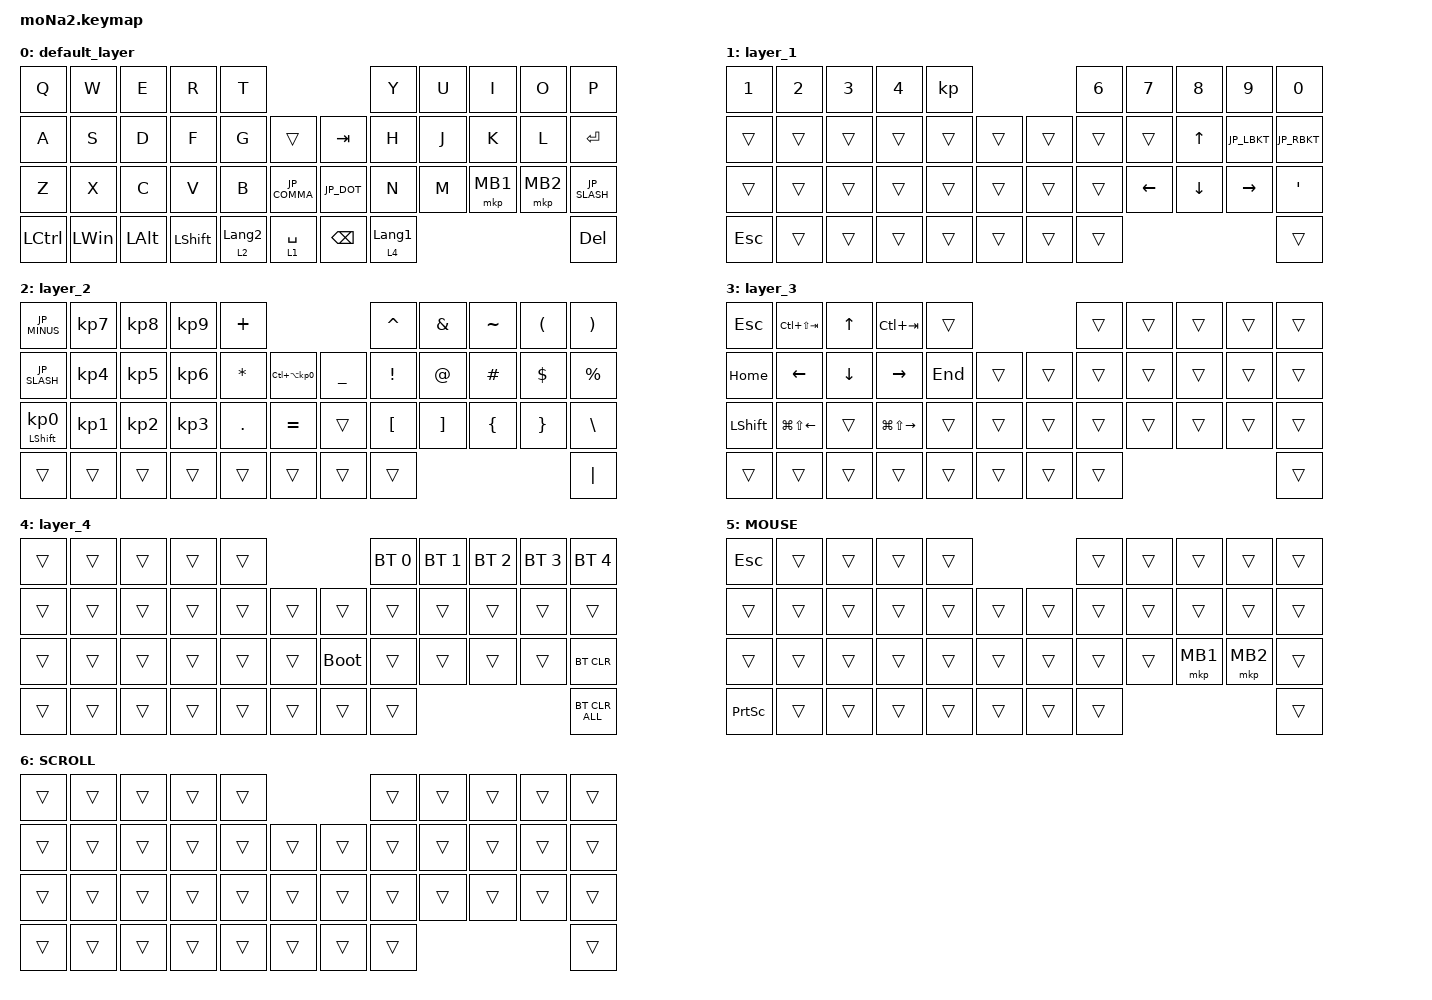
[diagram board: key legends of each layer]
#include <behaviors.dtsi>
#include <dt-bindings/zmk/bt.h>
#include <dt-bindings/zmk/keys.h>
#include <dt-bindings/zmk/pointing.h>

#define ZMK_POINTING_DEFAULT_SCRL_VAL 100
#define MOUSE 5
#define SCROLL 6

#define JP_ZKHK  GRAVE        // Zenkaku ↔ Hankaku ↔ Kanji (半角 ↔ 全角 ↔ 漢字)
#define JP_MINUS MINUS        // -
#define JP_CARET EQUAL        // ^
#define JP_YEN   INT3         // ¥
#define JP_AT    LBKT         // @
#define JP_LBKT  RBKT         // [
#define JP_EISU  CAPS         // Eisū (英数)
#define JP_SEMI  SEMI         // ;
#define JP_COLON SQT          // :
#define JP_RBKT  NUHS         // ]
#define JP_COMMA COMMA        // ,
#define JP_DOT   DOT          // .
#define JP_SLASH SLASH        // /
#define JP_BSLH  INT1         // (backslash)
#define JP_MHEN  INT5         // Muhenkan (無変換)
#define JP_HENK  INT4         // Henkan (変換)
#define JP_KANA  INT2         // Katakana ↔ Hiragana ↔ Rōmaji (カタカナ ↔ ひらがな ↔ ローマ字)
#define JP_EXCL  LS(N1)       // !
#define JP_DQT   LS(N2)       // "
#define JP_HASH  LS(N3)       // #
#define JP_DLLR  LS(N4)       // $
#define JP_PRCNT LS(N5)       // %
#define JP_AMPS  LS(N6)       // &
#define JP_SQT   LS(N7)       // '
#define JP_LPAR  LS(N8)       // (
#define JP_RPAR  LS(N9)       // )
#define JP_EQUAL LS(JP_MINUS) // =
#define JP_TILDE LS(JP_CARET) // ~
#define JP_PIPE  LS(JP_YEN)   // |
#define JP_GRAVE LS(JP_AT)    // `
#define JP_LBRC  LS(JP_LBKT)  // {
#define JP_CAPS  LS(JP_EISU)  // Caps Lock
#define JP_PLUS  LS(JP_SEMI)  // +
#define JP_ASTRK LS(JP_COLON) // *
#define JP_RBRC  LS(JP_RBKT)  // }
#define JP_LT    LS(JP_COMMA) // <
#define JP_RT    LS(JP_DOT)   // >
#define JP_QMARK LS(JP_SLASH) // ?
#define JP_UNDER LS(JP_BSLH)  // _

&mt {
    flavor = "balanced";
    quick-tap-ms = <0>;
};

/ {
    combos {
        compatible = "zmk,combos";

        minus {
            bindings = <&kp JP_MINUS>;
            key-positions = <7 6>;
            layers = <0>;
        };

        exclamation {
            bindings = <&kp JP_EXCL>;
            key-positions = <0 1>;
            layers = <0>;
        };

        question {
            bindings = <&kp JP_QMARK>;
            key-positions = <32 33>;
        };

        tab {
            bindings = <&kp TAB>;
            key-positions = <10 11>;
        };

        period {
            bindings = <&kp JP_DOT>;
            key-positions = <32 31>;
        };

        comma {
            bindings = <&kp JP_COMMA>;
            key-positions = <31 30>;
        };

        nyoro {
            bindings = <&kp JP_TILDE>;
            key-positions = <7 8>;
        };

        atmark {
            bindings = <&kp JP_AT>;
            key-positions = <19 20>;
        };

        colon {
            bindings = <&kp JP_COLON>;
            key-positions = <20 21>;
        };
    };

    macros {
        to_layer_0: to_layer_0 {
            compatible = "zmk,behavior-macro-one-param";
            #binding-cells = <1>;
            bindings = <&to 0 &macro_param_1to1 &kp MACRO_PLACEHOLDER>;
            label = "TO_LAYER_0";
        };
    };

    behaviors {
        lt_to_layer_0: lt_to_layer_0 {
            compatible = "zmk,behavior-hold-tap";
            label = "LAYER_TAP_TO_0";
            bindings = <&mo>, <&to_layer_0>;

            #binding-cells = <2>;
            tapping-term-ms = <200>;
        };

        scroll_up_down: behavior_sensor_rotate_mouse_wheel_up_down {
            compatible = "zmk,behavior-sensor-rotate";
            #sensor-binding-cells = <0>;
            bindings = <&msc SCRL_UP>, <&msc SCRL_DOWN>;

            tap-ms = <20>;
        };
    };

    keymap {
        compatible = "zmk,keymap";

        default_layer {
            bindings = <
&kp Q      &kp W         &kp E         &kp R                      &kp T                                      &kp Y             &kp U  &kp I     &kp O     &kp P
&kp A      &kp S         &kp D         &kp F                      &kp G        &trans         &kp TAB      &kp H             &kp J  &kp K     &kp L     &kp ENTER
&kp Z      &kp X         &kp C         &kp V                      &kp B        &kp JP_COMMA    &kp JP_DOT      &kp N             &kp M  &mkp MB1  &mkp MB2  &kp JP_SLASH
&kp LCTRL  &kp LEFT_WIN  &kp LEFT_ALT  &kp LEFT_SHIFT  &lt 2 LANGUAGE_2  &lt 1 SPACE      &kp BACKSPACE  &lt 4 LANGUAGE_1                             &kp DELETE
            >;

            sensor-bindings =
                <&scroll_up_down>,
                <&inc_dec_kp C_VOL_DN C_VOL_UP>;
        };

        layer_1 {
            bindings = <
&kp NUMBER_1  &kp NUMBER_2  &kp NUMBER_3  &kp NUMBER_4  &kp                     &kp NUMBER_6  &kp N7    &kp N8          &kp N9            &kp N0
&trans        &trans        &trans        &trans        &trans  &trans    &trans  &trans        &trans    &kp UP_ARROW    &kp JP_LBKT     &kp JP_RBKT
&trans        &trans        &trans        &trans        &trans  &trans    &trans  &trans        &kp LEFT  &kp DOWN_ARROW  &kp RIGHT         &kp SQT
&kp ESCAPE    &trans        &trans        &trans        &trans  &trans    &trans  &trans                                                    &trans
            >;

            sensor-bindings = <&scroll_up_down>;
        };

        layer_2 {
            bindings = <
&kp JP_MINUS                   &kp KP_NUMBER_7  &kp KP_NUMBER_8  &kp KP_NUMBER_9  &kp PLUS                                                 &kp CARET         &kp AMPERSAND      &kp TILDE       &kp LEFT_PARENTHESIS  &kp RIGHT_PARENTHESIS
&kp JP_SLASH                   &kp KP_NUMBER_4  &kp KP_NUMBER_5  &kp KP_NUMBER_6  &kp ASTERISK  &kp LC(LA(KP_NUMBER_0))    &kp UNDERSCORE  &kp EXCLAMATION   &kp AT_SIGN        &kp HASH        &kp DOLLAR            &kp PERCENT
&mt LEFT_SHIFT KP_NUMBER_0  &kp KP_NUMBER_1  &kp KP_NUMBER_2  &kp KP_NUMBER_3  &kp PERIOD    &kp EQUAL                  &trans          &kp LEFT_BRACKET  &kp RIGHT_BRACKET  &kp LEFT_BRACE  &kp RIGHT_BRACE       &kp BACKSLASH
&trans                      &trans           &trans           &trans           &trans        &trans                     &trans          &trans                                                                     &kp PIPE
            >;

            sensor-bindings = <&scroll_up_down>;
        };

        layer_3 {
            bindings = <
&kp ESCAPE      &kp LC(LS(TAB))         &kp UP_ARROW    &kp LC(TAB)              &trans                     &trans  &trans  &trans  &trans  &trans
&kp HOME        &kp LEFT_ARROW          &kp DOWN_ARROW  &kp RIGHT_ARROW          &kp END  &trans    &trans  &trans  &trans  &trans  &trans  &trans
&kp LEFT_SHIFT  &kp LG(LS(LEFT_ARROW))  &trans          &kp LG(LS(RIGHT_ARROW))  &trans   &trans    &trans  &trans  &trans  &trans  &trans  &trans
&trans          &trans                  &trans          &trans                   &trans   &trans    &trans  &trans                          &trans
            >;

            sensor-bindings = <&scroll_up_down>;
        };

        layer_4 {
            bindings = <
&trans  &trans  &trans  &trans  &trans                         &bt BT_SEL 0  &bt BT_SEL 1  &bt BT_SEL 2  &bt BT_SEL 3  &bt BT_SEL 4
&trans  &trans  &trans  &trans  &trans  &trans    &trans       &trans        &trans        &trans        &trans        &trans
&trans  &trans  &trans  &trans  &trans  &trans    &bootloader  &trans        &trans        &trans        &trans        &bt BT_CLR
&trans  &trans  &trans  &trans  &trans  &trans    &trans       &trans                                                  &bt BT_CLR_ALL
            >;

            sensor-bindings = <&scroll_up_down>;
        };

        MOUSE {
            bindings = <
&kp ESCAPE       &trans  &trans  &trans  &trans                    &trans  &trans  &trans    &trans    &trans
&trans           &trans  &trans  &trans  &trans  &trans    &trans  &trans  &trans  &trans    &trans    &trans
&trans           &trans  &trans  &trans  &trans  &trans    &trans  &trans  &trans  &mkp MB1  &mkp MB2  &trans
&kp PRINTSCREEN  &trans  &trans  &trans  &trans  &trans    &trans  &trans                              &trans
            >;

            sensor-bindings = <&scroll_up_down>;
        };

        SCROLL {
            bindings = <
&trans  &trans  &trans  &trans  &trans                    &trans  &trans  &trans  &trans  &trans
&trans  &trans  &trans  &trans  &trans  &trans    &trans  &trans  &trans  &trans  &trans  &trans
&trans  &trans  &trans  &trans  &trans  &trans    &trans  &trans  &trans  &trans  &trans  &trans
&trans  &trans  &trans  &trans  &trans  &trans    &trans  &trans                          &trans
            >;

            sensor-bindings = <&scroll_up_down>;
        };
    };
};
